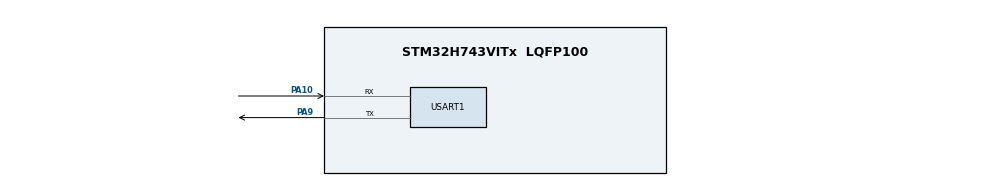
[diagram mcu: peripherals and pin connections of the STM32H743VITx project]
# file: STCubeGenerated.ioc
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CORTEX_M7.AccessPermission-Cortex_Memory_Protection_Unit_Region0_Settings=MPU_REGION_FULL_ACCESS
CORTEX_M7.CPU_DCache=Enabled
CORTEX_M7.CPU_ICache=Enabled
CORTEX_M7.Enable-Cortex_Memory_Protection_Unit_Region0_Settings=MPU_REGION_ENABLE
CORTEX_M7.IsBufferable-Cortex_Memory_Protection_Unit_Region0_Settings=MPU_ACCESS_BUFFERABLE
CORTEX_M7.IsCacheable-Cortex_Memory_Protection_Unit_Region0_Settings=MPU_ACCESS_CACHEABLE
CORTEX_M7.IsShareable-Cortex_Memory_Protection_Unit_Region0_Settings=MPU_ACCESS_SHAREABLE
CORTEX_M7.MPU_Control=MPU_PRIVILEGED_DEFAULT
CORTEX_M7.Size-Cortex_Memory_Protection_Unit_Region0_Settings=MPU_REGION_SIZE_64KB
CORTEX_M7.TypeExtField-Cortex_Memory_Protection_Unit_Region0_Settings=MPU_TEX_LEVEL1
Mcu.Family=STM32H7
Mcu.Name=STM32H743VITx
Mcu.Package=LQFP100
NVIC.PriorityGroup=NVIC_PRIORITYGROUP_4
PA10.Mode=Asynchronous
PA10.Signal=USART1_RX
PA9.Mode=Asynchronous
PA9.Signal=USART1_TX
ProjectManager.HeapSize=0x200
ProjectManager.StackSize=0x400
ProjectManager.TargetToolchain=Other Toolchains (GPDSC)
RCC.ADCFreq_Value=129000000
RCC.APB1Freq_Value=64000000
RCC.APB2Freq_Value=64000000
RCC.APB3Freq_Value=64000000
RCC.APB4Freq_Value=64000000
RCC.CortexFreq_Value=64000000
RCC.HCLKFreq_Value=64000000
RCC.SYSCLKFreq_VALUE=64000000
RCC.USBFreq_Value=129000000
USART1.VirtualMode-Asynchronous=VM_ASYNC
board=custom

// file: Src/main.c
/* USER CODE BEGIN Header */
/**
  ******************************************************************************
  * @file           : main.c
  * @brief          : Main program body
  ******************************************************************************
  ** This notice applies to any and all portions of this file
  * that are not between comment pairs USER CODE BEGIN and
  * USER CODE END. Other portions of this file, whether
  * inserted by the user or by software development tools
  * are owned by their respective copyright owners.
  *
  * COPYRIGHT(c) 2019 STMicroelectronics
  *
  * Redistribution and use in source and binary forms, with or without modification,
  * are permitted provided that the following conditions are met:
  *   1. Redistributions of source code must retain the above copyright notice,
  *      this list of conditions and the following disclaimer.
  *   2. Redistributions in binary form must reproduce the above copyright notice,
  *      this list of conditions and the following disclaimer in the documentation
  *      and/or other materials provided with the distribution.
  *   3. Neither the name of STMicroelectronics nor the names of its contributors
  *      may be used to endorse or promote products derived from this software
  *      without specific prior written permission.
  *
  * THIS SOFTWARE IS PROVIDED BY THE COPYRIGHT HOLDERS AND CONTRIBUTORS "AS IS"
  * AND ANY EXPRESS OR IMPLIED WARRANTIES, INCLUDING, BUT NOT LIMITED TO, THE
  * IMPLIED WARRANTIES OF MERCHANTABILITY AND FITNESS FOR A PARTICULAR PURPOSE ARE
  * DISCLAIMED. IN NO EVENT SHALL THE COPYRIGHT HOLDER OR CONTRIBUTORS BE LIABLE
  * FOR ANY DIRECT, INDIRECT, INCIDENTAL, SPECIAL, EXEMPLARY, OR CONSEQUENTIAL
  * DAMAGES (INCLUDING, BUT NOT LIMITED TO, PROCUREMENT OF SUBSTITUTE GOODS OR
  * SERVICES; LOSS OF USE, DATA, OR PROFITS; OR BUSINESS INTERRUPTION) HOWEVER
  * CAUSED AND ON ANY THEORY OF LIABILITY, WHETHER IN CONTRACT, STRICT LIABILITY,
  * OR TORT (INCLUDING NEGLIGENCE OR OTHERWISE) ARISING IN ANY WAY OUT OF THE USE
  * OF THIS SOFTWARE, EVEN IF ADVISED OF THE POSSIBILITY OF SUCH DAMAGE.
  *
  ******************************************************************************
  */
/* USER CODE END Header */

#include "main.h"
#include "usart.h"
#include "gpio.h"

void SystemClock_Config(void);
static void MPU_Config(void);

int main(void)
{

  /* MPU Configuration--------------------------------------------------------*/
  MPU_Config();

  /* Enable I-Cache---------------------------------------------------------*/
  SCB_EnableICache();

  /* Enable D-Cache---------------------------------------------------------*/
  SCB_EnableDCache();

  /* MCU Configuration--------------------------------------------------------*/

  /* Reset of all peripherals, Initializes the Flash interface and the Systick. */
  HAL_Init();

  /* Configure the system clock */
  SystemClock_Config();

  /* Initialize all configured peripherals */
  MX_GPIO_Init();
  MX_USART1_UART_Init();
  /* USER CODE BEGIN 2 */
	HAL_UART_Transmit(&huart1,(uint8_t *)"Helloworld",11,HAL_MAX_DELAY);
  /* USER CODE END 2 */

  /* Infinite loop */
  while (1)
  {
		HAL_UART_Transmit(&huart1,(uint8_t *)"Helloworld",11,HAL_MAX_DELAY);

  }
}

void SystemClock_Config(void)
{
  RCC_OscInitTypeDef RCC_OscInitStruct = {0};
  RCC_ClkInitTypeDef RCC_ClkInitStruct = {0};
  RCC_PeriphCLKInitTypeDef PeriphClkInitStruct = {0};

  /**Supply configuration update enable
  */
  MODIFY_REG(PWR->CR3, PWR_CR3_SCUEN, 0);
  /**Configure the main internal regulator output voltage
  */
  __HAL_PWR_VOLTAGESCALING_CONFIG(PWR_REGULATOR_VOLTAGE_SCALE3);

  while ((PWR->D3CR & (PWR_D3CR_VOSRDY)) != PWR_D3CR_VOSRDY)
  {

  }
  /**Initializes the CPU, AHB and APB busses clocks
  */
  RCC_OscInitStruct.OscillatorType = RCC_OSCILLATORTYPE_HSI;
  RCC_OscInitStruct.HSIState = RCC_HSI_DIV1;
  RCC_OscInitStruct.HSICalibrationValue = RCC_HSICALIBRATION_DEFAULT;
  RCC_OscInitStruct.PLL.PLLState = RCC_PLL_NONE;
  if (HAL_RCC_OscConfig(&RCC_OscInitStruct) != HAL_OK)
  {
    Error_Handler();
  }
  /**Initializes the CPU, AHB and APB busses clocks
  */
  RCC_ClkInitStruct.ClockType = RCC_CLOCKTYPE_HCLK|RCC_CLOCKTYPE_SYSCLK
                              |RCC_CLOCKTYPE_PCLK1|RCC_CLOCKTYPE_PCLK2
                              |RCC_CLOCKTYPE_D3PCLK1|RCC_CLOCKTYPE_D1PCLK1;
  RCC_ClkInitStruct.SYSCLKSource = RCC_SYSCLKSOURCE_HSI;
  RCC_ClkInitStruct.SYSCLKDivider = RCC_SYSCLK_DIV1;
  RCC_ClkInitStruct.AHBCLKDivider = RCC_HCLK_DIV1;
  RCC_ClkInitStruct.APB3CLKDivider = RCC_APB3_DIV1;
  RCC_ClkInitStruct.APB1CLKDivider = RCC_APB1_DIV1;
  RCC_ClkInitStruct.APB2CLKDivider = RCC_APB2_DIV1;
  RCC_ClkInitStruct.APB4CLKDivider = RCC_APB4_DIV1;

  if (HAL_RCC_ClockConfig(&RCC_ClkInitStruct, FLASH_LATENCY_0) != HAL_OK)
  {
    Error_Handler();
  }
  PeriphClkInitStruct.PeriphClockSelection = RCC_PERIPHCLK_USART1;
  PeriphClkInitStruct.Usart16ClockSelection = RCC_USART16CLKSOURCE_D2PCLK2;
  if (HAL_RCCEx_PeriphCLKConfig(&PeriphClkInitStruct) != HAL_OK)
  {
    Error_Handler();
  }
}

/* MPU Configuration */

void MPU_Config(void)
{
  MPU_Region_InitTypeDef MPU_InitStruct = {0};

  /* Disables the MPU */
  HAL_MPU_Disable();
  /**Initializes and configures the Region and the memory to be protected
  */
  MPU_InitStruct.Enable = MPU_REGION_ENABLE;
  MPU_InitStruct.Number = MPU_REGION_NUMBER0;
  MPU_InitStruct.BaseAddress = 0x0;
  MPU_InitStruct.Size = MPU_REGION_SIZE_64KB;
  MPU_InitStruct.SubRegionDisable = 0x0;
  MPU_InitStruct.TypeExtField = MPU_TEX_LEVEL1;
  MPU_InitStruct.AccessPermission = MPU_REGION_FULL_ACCESS;
  MPU_InitStruct.DisableExec = MPU_INSTRUCTION_ACCESS_ENABLE;
  MPU_InitStruct.IsShareable = MPU_ACCESS_SHAREABLE;
  MPU_InitStruct.IsCacheable = MPU_ACCESS_CACHEABLE;
  MPU_InitStruct.IsBufferable = MPU_ACCESS_BUFFERABLE;

  HAL_MPU_ConfigRegion(&MPU_InitStruct);
  /* Enables the MPU */
  HAL_MPU_Enable(MPU_PRIVILEGED_DEFAULT);

}

void Error_Handler(void)
{
}

/************************ (C) COPYRIGHT STMicroelectronics *****END OF FILE****/
